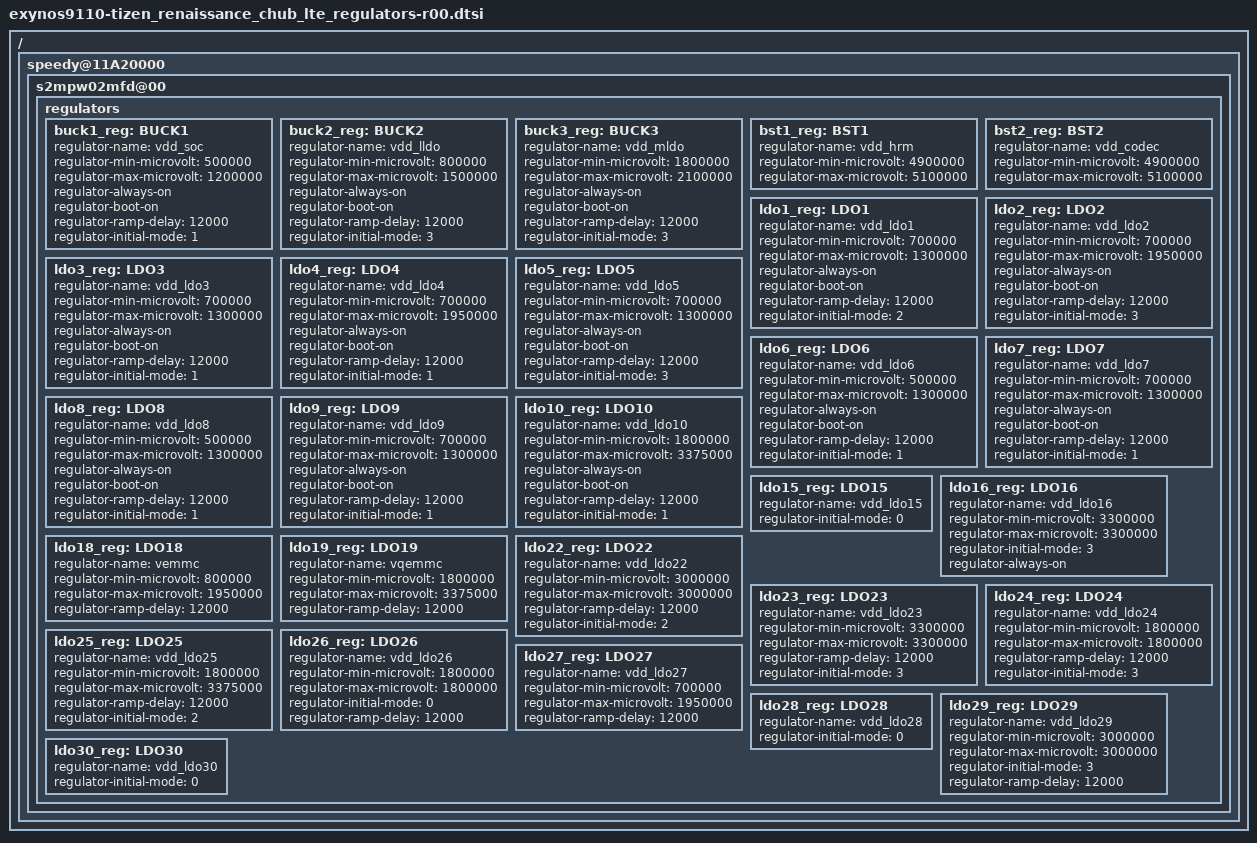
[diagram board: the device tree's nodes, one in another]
/*
 * SAMSUNG EXYNOS9110 board S2MPW02 regulators device tree source
 *
 * Copyright (c) 2017 Samsung Electronics Co., Ltd.
 *		http://www.samsung.com
 *
 * This program is free software; you can redistribute it and/or modify
 * it under the terms of the GNU General Public License version 2 as
 * published by the Free Software Foundation.
 */

/ {
	speedy@11A20000{
		s2mpw02mfd@00 {
			regulators {
				buck1_reg: BUCK1 {
					regulator-name = "vdd_soc";
					regulator-min-microvolt = <500000>;
					regulator-max-microvolt = <1200000>;
					regulator-always-on;
					regulator-boot-on;
					regulator-ramp-delay = <12000>;
					regulator-initial-mode = <1>;
				};
				buck2_reg: BUCK2 {
					regulator-name = "vdd_lldo";
					regulator-min-microvolt = <800000>;
					regulator-max-microvolt = <1500000>;
					regulator-always-on;
					regulator-boot-on;
					regulator-ramp-delay = <12000>;
					regulator-initial-mode = <3>;
				};

				buck3_reg: BUCK3 {
					regulator-name = "vdd_mldo";
					regulator-min-microvolt = <1800000>;
					regulator-max-microvolt = <2100000>;
					regulator-always-on;
					regulator-boot-on;
					regulator-ramp-delay = <12000>;
					regulator-initial-mode = <3>;
				};

				bst1_reg: BST1 {
					regulator-name = "vdd_hrm";
					regulator-min-microvolt = <4900000>;
					regulator-max-microvolt = <5100000>;
				};

				bst2_reg: BST2 {
					regulator-name = "vdd_codec";
					regulator-min-microvolt = <4900000>;
					regulator-max-microvolt = <5100000>;
				};

				ldo1_reg: LDO1 {
					regulator-name = "vdd_ldo1";
					regulator-min-microvolt = <700000>;
					regulator-max-microvolt = <1300000>;
					regulator-always-on;
					regulator-boot-on;
					regulator-ramp-delay = <12000>;
					regulator-initial-mode = <2>;
				};

				ldo2_reg: LDO2 {
					regulator-name = "vdd_ldo2";
					regulator-min-microvolt = <700000>;
					regulator-max-microvolt = <1950000>;
					regulator-always-on;
					regulator-boot-on;
					regulator-ramp-delay = <12000>;
					regulator-initial-mode = <3>;
				};

				ldo3_reg: LDO3 {
					regulator-name = "vdd_ldo3";
					regulator-min-microvolt = <700000>;
					regulator-max-microvolt = <1300000>;
					regulator-always-on;
					regulator-boot-on;
					regulator-ramp-delay = <12000>;
					regulator-initial-mode = <1>;
				};

				ldo4_reg: LDO4 {
					regulator-name = "vdd_ldo4";
					regulator-min-microvolt = <700000>;
					regulator-max-microvolt = <1950000>;
					regulator-always-on;
					regulator-boot-on;
					regulator-ramp-delay = <12000>;
					regulator-initial-mode = <1>;
				};

				ldo5_reg: LDO5 {
					regulator-name = "vdd_ldo5";
					regulator-min-microvolt = <700000>;
					regulator-max-microvolt = <1300000>;
					regulator-always-on;
					regulator-boot-on;
					regulator-ramp-delay = <12000>;
					regulator-initial-mode = <3>;
				};

				ldo6_reg: LDO6 {
					regulator-name = "vdd_ldo6";
					regulator-min-microvolt = <500000>;
					regulator-max-microvolt = <1300000>;
					regulator-always-on;
					regulator-boot-on;
					regulator-ramp-delay = <12000>;
					regulator-initial-mode = <1>;
				};

				ldo7_reg: LDO7 {
					regulator-name = "vdd_ldo7";
					regulator-min-microvolt = <700000>;
					regulator-max-microvolt = <1300000>;
					regulator-always-on;
					regulator-boot-on;
					regulator-ramp-delay = <12000>;
					regulator-initial-mode = <1>;
				};

				ldo8_reg: LDO8 {
					regulator-name = "vdd_ldo8";
					regulator-min-microvolt = <500000>;
					regulator-max-microvolt = <1300000>;
					regulator-always-on;
					regulator-boot-on;
					regulator-ramp-delay = <12000>;
					regulator-initial-mode = <1>;
				};

				ldo9_reg: LDO9 {
					regulator-name = "vdd_ldo9";
					regulator-min-microvolt = <700000>;
					regulator-max-microvolt = <1300000>;
					regulator-always-on;
					regulator-boot-on;
					regulator-ramp-delay = <12000>;
					regulator-initial-mode = <1>;
				};

				ldo10_reg: LDO10 {
					regulator-name = "vdd_ldo10";
					regulator-min-microvolt = <1800000>;
					regulator-max-microvolt = <3375000>;
					regulator-always-on;
					regulator-boot-on;
					regulator-ramp-delay = <12000>;
					regulator-initial-mode = <1>;
				};

				ldo15_reg: LDO15 {
					regulator-name = "vdd_ldo15";
					regulator-initial-mode = <0>;
				};

				ldo16_reg: LDO16 {
					regulator-name = "vdd_ldo16";
					regulator-min-microvolt = <3300000>;
					regulator-max-microvolt = <3300000>;
					regulator-initial-mode = <3>;
					regulator-always-on;
				};

				ldo18_reg: LDO18 {
					regulator-name = "vemmc";
					regulator-min-microvolt = <800000>;
					regulator-max-microvolt = <1950000>;
					regulator-ramp-delay = <12000>;
				};

				ldo19_reg: LDO19 {
					regulator-name = "vqemmc";
					regulator-min-microvolt = <1800000>;
					regulator-max-microvolt = <3375000>;
					regulator-ramp-delay = <12000>;
				};

				ldo22_reg: LDO22 {
					regulator-name = "vdd_ldo22";
					regulator-min-microvolt = <3000000>;
					regulator-max-microvolt = <3000000>;
					regulator-ramp-delay = <12000>;
					regulator-initial-mode = <2>;
				};

				ldo23_reg: LDO23 {
					regulator-name = "vdd_ldo23";
					regulator-min-microvolt = <3300000>;
					regulator-max-microvolt = <3300000>;
					regulator-ramp-delay = <12000>;
					regulator-initial-mode = <3>;
				};

				ldo24_reg: LDO24 {
					regulator-name = "vdd_ldo24";
					regulator-min-microvolt = <1800000>;
					regulator-max-microvolt = <1800000>;
					regulator-ramp-delay = <12000>;
					regulator-initial-mode = <3>;
				};

				ldo25_reg: LDO25 {
					regulator-name = "vdd_ldo25";
					regulator-min-microvolt = <1800000>;
					regulator-max-microvolt = <3375000>;
					regulator-ramp-delay = <12000>;
					regulator-initial-mode = <2>;
				};

				ldo26_reg: LDO26 {
					regulator-name = "vdd_ldo26";
					regulator-min-microvolt = <1800000>;
					regulator-max-microvolt = <1800000>;
					regulator-initial-mode = <0>;
					regulator-ramp-delay = <12000>;
				};

				ldo27_reg: LDO27 {
					regulator-name = "vdd_ldo27";
					regulator-min-microvolt = <700000>;
					regulator-max-microvolt = <1950000>;
					regulator-ramp-delay = <12000>;
				};

				ldo28_reg: LDO28 {
					regulator-name = "vdd_ldo28";
					regulator-initial-mode = <0>;
				};

				ldo29_reg: LDO29 {
					regulator-name = "vdd_ldo29";
					regulator-min-microvolt = <3000000>;
					regulator-max-microvolt = <3000000>;
					regulator-initial-mode = <3>;
					regulator-ramp-delay = <12000>;
				};

				ldo30_reg: LDO30 {
					regulator-name = "vdd_ldo30";
					regulator-initial-mode = <0>;
				};
			};
		};
	};
};
